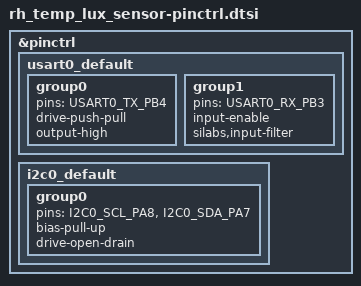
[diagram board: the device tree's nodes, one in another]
#include <zephyr/dt-bindings/pinctrl/silabs/xg26-pinctrl.h>

&pinctrl {
	/* Debug UART (console): DBG_TX on PB04, DBG_RX on PB03 */
	usart0_default: usart0_default {
		group0 {
			pins = <USART0_TX_PB4>;
			drive-push-pull;
			output-high;
		};

		group1 {
			pins = <USART0_RX_PB3>;
			input-enable;
			silabs,input-filter;
		};
	};

	/* I2C0: SDA on PA07, SCL on PA08 (DS1308, VEML6030, SHT40) */
	i2c0_default: i2c0_default {
		group0 {
			pins = <I2C0_SCL_PA8>, <I2C0_SDA_PA7>;
			bias-pull-up;
			drive-open-drain;
		};
	};
};
